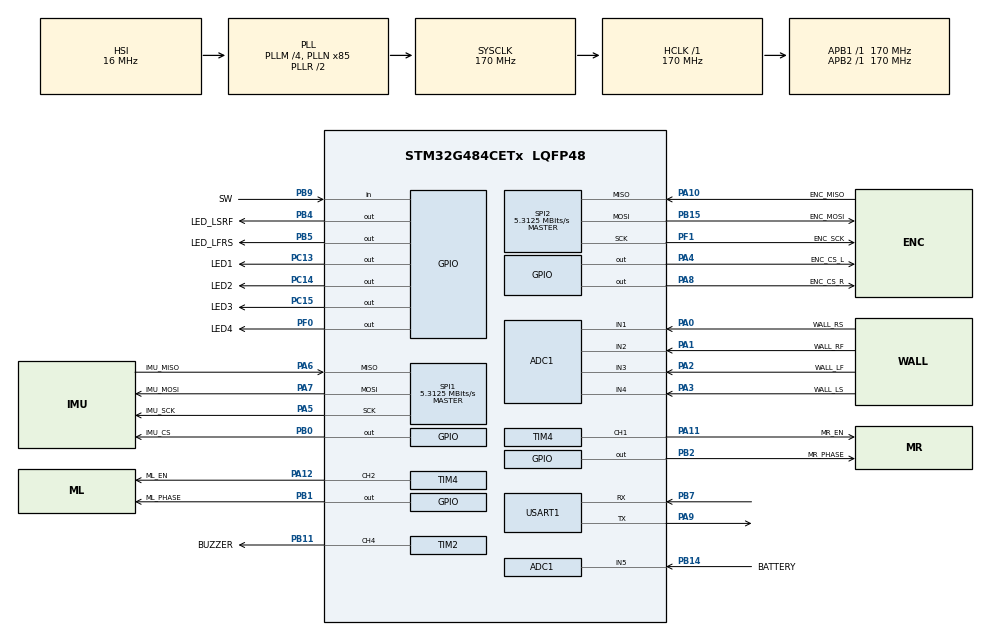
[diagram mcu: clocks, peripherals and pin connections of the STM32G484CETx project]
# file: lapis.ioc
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ADC1.Channel-0\#ChannelRegularConversion=ADC_CHANNEL_1
ADC1.Channel-1\#ChannelRegularConversion=ADC_CHANNEL_2
ADC1.Channel-2\#ChannelRegularConversion=ADC_CHANNEL_3
ADC1.Channel-3\#ChannelRegularConversion=ADC_CHANNEL_4
ADC1.Channel-4\#ChannelRegularConversion=ADC_CHANNEL_5
ADC1.ClockPrescaler=ADC_CLOCK_ASYNC_DIV4
ADC1.ContinuousConvMode=ENABLE
ADC1.DMAContinuousRequests=ENABLE
ADC1.NbrOfConversion=5
ADC1.NbrOfConversionFlag=1
ADC1.OffsetNumber-0\#ChannelRegularConversion=ADC_OFFSET_NONE
ADC1.OffsetNumber-1\#ChannelRegularConversion=ADC_OFFSET_NONE
ADC1.OffsetNumber-2\#ChannelRegularConversion=ADC_OFFSET_NONE
ADC1.OffsetNumber-3\#ChannelRegularConversion=ADC_OFFSET_NONE
ADC1.OffsetNumber-4\#ChannelRegularConversion=ADC_OFFSET_NONE
ADC1.Rank-0\#ChannelRegularConversion=1
ADC1.Rank-1\#ChannelRegularConversion=2
ADC1.Rank-2\#ChannelRegularConversion=3
ADC1.Rank-3\#ChannelRegularConversion=4
ADC1.Rank-4\#ChannelRegularConversion=5
ADC1.SamplingTime-0\#ChannelRegularConversion=ADC_SAMPLETIME_47CYCLES_5
ADC1.SamplingTime-1\#ChannelRegularConversion=ADC_SAMPLETIME_47CYCLES_5
ADC1.SamplingTime-2\#ChannelRegularConversion=ADC_SAMPLETIME_47CYCLES_5
ADC1.SamplingTime-3\#ChannelRegularConversion=ADC_SAMPLETIME_47CYCLES_5
ADC1.SamplingTime-4\#ChannelRegularConversion=ADC_SAMPLETIME_47CYCLES_5
ADC1.master=1
Dma.ADC1.0.Direction=DMA_PERIPH_TO_MEMORY
Dma.ADC1.0.EventEnable=DISABLE
Dma.ADC1.0.Instance=DMA1_Channel1
Dma.ADC1.0.MemDataAlignment=DMA_MDATAALIGN_HALFWORD
Dma.ADC1.0.MemInc=DMA_MINC_ENABLE
Dma.ADC1.0.Mode=DMA_CIRCULAR
Dma.ADC1.0.PeriphDataAlignment=DMA_PDATAALIGN_HALFWORD
Dma.ADC1.0.PeriphInc=DMA_PINC_DISABLE
Dma.ADC1.0.Polarity=HAL_DMAMUX_REQ_GEN_RISING
Dma.ADC1.0.Priority=DMA_PRIORITY_LOW
Dma.ADC1.0.RequestNumber=1
Dma.ADC1.0.SignalID=NONE
Dma.ADC1.0.SyncEnable=DISABLE
Dma.ADC1.0.SyncPolarity=HAL_DMAMUX_SYNC_NO_EVENT
Dma.ADC1.0.SyncRequestNumber=1
Dma.ADC1.0.SyncSignalID=NONE
Dma.Request0=ADC1
Dma.Request1=USART1_TX
Dma.USART1_TX.1.Direction=DMA_MEMORY_TO_PERIPH
Dma.USART1_TX.1.EventEnable=DISABLE
Dma.USART1_TX.1.Instance=DMA2_Channel1
Dma.USART1_TX.1.MemDataAlignment=DMA_MDATAALIGN_BYTE
Dma.USART1_TX.1.MemInc=DMA_MINC_ENABLE
Dma.USART1_TX.1.Mode=DMA_NORMAL
Dma.USART1_TX.1.PeriphDataAlignment=DMA_PDATAALIGN_BYTE
Dma.USART1_TX.1.PeriphInc=DMA_PINC_DISABLE
Dma.USART1_TX.1.Polarity=HAL_DMAMUX_REQ_GEN_RISING
Dma.USART1_TX.1.Priority=DMA_PRIORITY_LOW
Dma.USART1_TX.1.RequestNumber=1
Dma.USART1_TX.1.SignalID=NONE
Dma.USART1_TX.1.SyncEnable=DISABLE
Dma.USART1_TX.1.SyncPolarity=HAL_DMAMUX_SYNC_NO_EVENT
Dma.USART1_TX.1.SyncRequestNumber=1
Dma.USART1_TX.1.SyncSignalID=NONE
Mcu.Family=STM32G4
Mcu.Name=STM32G484CETx
Mcu.Package=LQFP48
NVIC.DMA1_Channel1_IRQn=true\:1\:0\:true\:false\:true\:false\:true\:true
NVIC.DMA2_Channel1_IRQn=true\:0\:0\:false\:false\:true\:false\:true\:true
NVIC.FLASH_IRQn=true\:0\:0\:false\:false\:true\:true\:true\:true
NVIC.PriorityGroup=NVIC_PRIORITYGROUP_4
NVIC.TIM1_BRK_TIM15_IRQn=true\:0\:0\:true\:false\:true\:true\:true\:true
NVIC.TIM1_CC_IRQn=true\:0\:0\:false\:false\:true\:true\:true\:true
NVIC.TIM1_TRG_COM_TIM17_IRQn=true\:0\:0\:false\:false\:true\:true\:true\:true
NVIC.TIM1_UP_TIM16_IRQn=true\:0\:0\:true\:false\:true\:true\:true\:true
NVIC.TIM3_IRQn=true\:0\:0\:true\:false\:true\:true\:true\:true
NVIC.TIM5_IRQn=true\:0\:0\:true\:false\:true\:true\:true\:true
PA0.GPIO_Label=WALL_RS
PA0.Mode=IN1-Single-Ended
PA0.Signal=ADC1_IN1
PA1.GPIO_Label=WALL_RF
PA1.Mode=IN2-Single-Ended
PA1.Signal=ADC1_IN2
PA10.GPIO_Label=ENC_MISO
PA10.Mode=Full_Duplex_Master
PA10.Signal=SPI2_MISO
PA11.GPIO_Label=MR_EN
PA11.Signal=S_TIM4_CH1
PA12.GPIO_Label=ML_EN
PA12.Signal=S_TIM4_CH2
PA13.Mode=Serial_Wire
PA13.Signal=SYS_JTMS-SWDIO
PA14.Mode=Serial_Wire
PA14.Signal=SYS_JTCK-SWCLK
PA2.GPIO_Label=WALL_LF
PA2.Mode=IN3-Single-Ended
PA2.Signal=ADC1_IN3
PA3.GPIO_Label=WALL_LS
PA3.Mode=IN4-Single-Ended
PA3.Signal=ADC1_IN4
PA4.GPIO_Label=ENC_CS_L
PA4.Signal=GPIO_Output
PA5.GPIO_Label=IMU_SCK
PA5.Mode=Full_Duplex_Master
PA5.Signal=SPI1_SCK
PA6.GPIO_Label=IMU_MISO
PA6.Mode=Full_Duplex_Master
PA6.Signal=SPI1_MISO
PA7.GPIO_Label=IMU_MOSI
PA7.Mode=Full_Duplex_Master
PA7.Signal=SPI1_MOSI
PA8.GPIO_Label=ENC_CS_R
PA8.Signal=GPIO_Output
PA9.Mode=Asynchronous
PA9.Signal=USART1_TX
PB0.GPIO_Label=IMU_CS
PB0.Signal=GPIO_Output
PB1.GPIO_Label=ML_PHASE
PB1.Signal=GPIO_Output
PB11.GPIO_Label=BUZZER
PB11.Signal=S_TIM2_CH4
PB14.GPIO_Label=BATTERY
PB14.Mode=IN5-Single-Ended
PB14.Signal=ADC1_IN5
PB15.GPIO_Label=ENC_MOSI
PB15.Mode=Full_Duplex_Master
PB15.Signal=SPI2_MOSI
PB2.GPIO_Label=MR_PHASE
PB2.Signal=GPIO_Output
PB4.GPIO_Label=LED_LSRF
PB4.Signal=GPIO_Output
PB5.GPIO_Label=LED_LFRS
PB5.Signal=GPIO_Output
PB7.Mode=Asynchronous
PB7.Signal=USART1_RX
PB9.GPIO_Label=SW
PB9.Signal=GPIO_Input
PC13.GPIO_Label=LED1
PC13.Signal=GPIO_Output
PC14-OSC32_IN.GPIO_Label=LED2
PC14-OSC32_IN.Signal=GPIO_Output
PC15-OSC32_OUT.GPIO_Label=LED3
PC15-OSC32_OUT.Signal=GPIO_Output
PF0-OSC_IN.GPIO_Label=LED4
PF0-OSC_IN.Signal=GPIO_Output
PF1-OSC_OUT.GPIO_Label=ENC_SCK
PF1-OSC_OUT.Mode=Full_Duplex_Master
PF1-OSC_OUT.Signal=SPI2_SCK
ProjectManager.HeapSize=0x200
ProjectManager.StackSize=0x400
ProjectManager.TargetToolchain=STM32CubeIDE
RCC.ADC12Freq_Value=170000000
RCC.ADC345Freq_Value=170000000
RCC.AHBFreq_Value=170000000
RCC.APB1Freq_Value=170000000
RCC.APB1TimFreq_Value=170000000
RCC.APB2Freq_Value=170000000
RCC.APB2TimFreq_Value=170000000
RCC.CortexFreq_Value=170000000
RCC.EXTERNAL_CLOCK_VALUE=12288000
RCC.HCLKFreq_Value=170000000
RCC.HSE_VALUE=8000000
RCC.HSI48_VALUE=48000000
RCC.HSI_VALUE=16000000
RCC.LSE_VALUE=32768
RCC.PLLM=RCC_PLLM_DIV4
RCC.PLLN=85
RCC.SYSCLKFreq_VALUE=170000000
RCC.SYSCLKSource=RCC_SYSCLKSOURCE_PLLCLK
RCC.USBFreq_Value=170000000
RCC.VCOOutputFreq_Value=340000000
SH.S_TIM2_CH4.0=TIM2_CH4,PWM Generation4 CH4
SH.S_TIM4_CH1.0=TIM4_CH1,PWM Generation1 CH1
SH.S_TIM4_CH2.0=TIM4_CH2,PWM Generation2 CH2
SPI1.BaudRatePrescaler=SPI_BAUDRATEPRESCALER_32
SPI1.CalculateBaudRate=5.3125 MBits/s
SPI1.DataSize=SPI_DATASIZE_8BIT
SPI1.Direction=SPI_DIRECTION_2LINES
SPI1.Mode=SPI_MODE_MASTER
SPI1.VirtualType=VM_MASTER
SPI2.BaudRatePrescaler=SPI_BAUDRATEPRESCALER_32
SPI2.CLKPhase=SPI_PHASE_2EDGE
SPI2.CalculateBaudRate=5.3125 MBits/s
SPI2.DataSize=SPI_DATASIZE_16BIT
SPI2.Direction=SPI_DIRECTION_2LINES
SPI2.Mode=SPI_MODE_MASTER
SPI2.VirtualType=VM_MASTER
TIM1.PeriodNoDither=169
TIM1.Prescaler=999
TIM2.Channel-PWM\ Generation4\ CH4=TIM_CHANNEL_4
TIM2.PeriodNoDither=0
TIM2.Prescaler=0
TIM3.PeriodNoDither=424
TIM3.Prescaler=99
TIM4.Channel-PWM\ Generation1\ CH1=TIM_CHANNEL_1
TIM4.Channel-PWM\ Generation2\ CH2=TIM_CHANNEL_2
TIM4.PeriodNoDither=999
TIM5.PeriodNoDither=169
TIM5.Prescaler=999
USART1.VirtualMode-Asynchronous=VM_ASYNC
VP_SYS_VS_DBSignals.Mode=DisableDeadBatterySignals
VP_TIM1_VS_ClockSourceINT.Mode=Internal
VP_TIM3_VS_ClockSourceINT.Mode=Internal
VP_TIM5_VS_ClockSourceINT.Mode=Internal
board=custom

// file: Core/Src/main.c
/* USER CODE BEGIN Header */
/**
 ******************************************************************************
 * @file           : main.c
 * @brief          : Main program body
 ******************************************************************************
 * @attention
 *
 * <h2><center>&copy; Copyright (c) 2021 STMicroelectronics.
 * All rights reserved.</center></h2>
 *
 * This software component is licensed by ST under BSD 3-Clause license,
 * the "License"; You may not use this file except in compliance with the
 * License. You may obtain a copy of the License at:
 *                        opensource.org/licenses/BSD-3-Clause
 *
 ******************************************************************************
 */
/* USER CODE END Header */
#include "main.h"

/* USER CODE BEGIN Includes */
#include"ICM20602.h"
#include "AS5047P.h"
#include"timer.h"
#include"lapis.h"
#include"motor.h"
#include "wallsensor.h"
#include"adc.h"
#include"UI.h"
/* USER CODE END Includes */

 ADC_HandleTypeDef hadc1;
DMA_HandleTypeDef hdma_adc1;

SPI_HandleTypeDef hspi1;
SPI_HandleTypeDef hspi2;

TIM_HandleTypeDef htim1;
TIM_HandleTypeDef htim2;
TIM_HandleTypeDef htim3;
TIM_HandleTypeDef htim4;
TIM_HandleTypeDef htim5;

UART_HandleTypeDef huart1;
DMA_HandleTypeDef hdma_usart1_tx;

void SystemClock_Config(void);
static void MX_GPIO_Init(void);
static void MX_DMA_Init(void);
static void MX_ADC1_Init(void);
static void MX_SPI1_Init(void);
static void MX_SPI2_Init(void);
static void MX_TIM1_Init(void);
static void MX_TIM2_Init(void);
static void MX_TIM4_Init(void);
static void MX_USART1_UART_Init(void);
static void MX_TIM3_Init(void);
static void MX_TIM5_Init(void);

int main(void)
{

  /* MCU Configuration--------------------------------------------------------*/

  /* Reset of all peripherals, Initializes the Flash interface and the Systick. */
  HAL_Init();

  /* Configure the system clock */
  SystemClock_Config();

  /* Initialize all configured peripherals */
  MX_GPIO_Init();
  MX_DMA_Init();
  MX_ADC1_Init();
  MX_SPI1_Init();
  MX_SPI2_Init();
  MX_TIM1_Init();
  MX_TIM2_Init();
  MX_TIM4_Init();
  MX_USART1_UART_Init();
  MX_TIM3_Init();
  MX_TIM5_Init();

  /* Infinite loop */
	while (1) {

    /* USER CODE BEGIN 3 */

		lapis();
	}
  /* USER CODE END 3 */
}

void SystemClock_Config(void)
{
  RCC_OscInitTypeDef RCC_OscInitStruct = {0};
  RCC_ClkInitTypeDef RCC_ClkInitStruct = {0};

  /** Configure the main internal regulator output voltage
  */
  HAL_PWREx_ControlVoltageScaling(PWR_REGULATOR_VOLTAGE_SCALE1_BOOST);

  /** Initializes the RCC Oscillators according to the specified parameters
  * in the RCC_OscInitTypeDef structure.
  */
  RCC_OscInitStruct.OscillatorType = RCC_OSCILLATORTYPE_HSI;
  RCC_OscInitStruct.HSIState = RCC_HSI_ON;
  RCC_OscInitStruct.HSICalibrationValue = RCC_HSICALIBRATION_DEFAULT;
  RCC_OscInitStruct.PLL.PLLState = RCC_PLL_ON;
  RCC_OscInitStruct.PLL.PLLSource = RCC_PLLSOURCE_HSI;
  RCC_OscInitStruct.PLL.PLLM = RCC_PLLM_DIV4;
  RCC_OscInitStruct.PLL.PLLN = 85;
  RCC_OscInitStruct.PLL.PLLP = RCC_PLLP_DIV2;
  RCC_OscInitStruct.PLL.PLLQ = RCC_PLLQ_DIV2;
  RCC_OscInitStruct.PLL.PLLR = RCC_PLLR_DIV2;
  if (HAL_RCC_OscConfig(&RCC_OscInitStruct) != HAL_OK)
  {
    Error_Handler();
  }

  /** Initializes the CPU, AHB and APB buses clocks
  */
  RCC_ClkInitStruct.ClockType = RCC_CLOCKTYPE_HCLK|RCC_CLOCKTYPE_SYSCLK
                              |RCC_CLOCKTYPE_PCLK1|RCC_CLOCKTYPE_PCLK2;
  RCC_ClkInitStruct.SYSCLKSource = RCC_SYSCLKSOURCE_PLLCLK;
  RCC_ClkInitStruct.AHBCLKDivider = RCC_SYSCLK_DIV1;
  RCC_ClkInitStruct.APB1CLKDivider = RCC_HCLK_DIV1;
  RCC_ClkInitStruct.APB2CLKDivider = RCC_HCLK_DIV1;

  if (HAL_RCC_ClockConfig(&RCC_ClkInitStruct, FLASH_LATENCY_4) != HAL_OK)
  {
    Error_Handler();
  }
}

static void MX_ADC1_Init(void)
{

  ADC_MultiModeTypeDef multimode = {0};
  ADC_ChannelConfTypeDef sConfig = {0};

  /** Common config
  */
  hadc1.Instance = ADC1;
  hadc1.Init.ClockPrescaler = ADC_CLOCK_ASYNC_DIV4;
  hadc1.Init.Resolution = ADC_RESOLUTION_12B;
  hadc1.Init.DataAlign = ADC_DATAALIGN_RIGHT;
  hadc1.Init.GainCompensation = 0;
  hadc1.Init.ScanConvMode = ADC_SCAN_ENABLE;
  hadc1.Init.EOCSelection = ADC_EOC_SINGLE_CONV;
  hadc1.Init.LowPowerAutoWait = DISABLE;
  hadc1.Init.ContinuousConvMode = ENABLE;
  hadc1.Init.NbrOfConversion = 5;
  hadc1.Init.DiscontinuousConvMode = DISABLE;
  hadc1.Init.ExternalTrigConv = ADC_SOFTWARE_START;
  hadc1.Init.ExternalTrigConvEdge = ADC_EXTERNALTRIGCONVEDGE_NONE;
  hadc1.Init.DMAContinuousRequests = ENABLE;
  hadc1.Init.Overrun = ADC_OVR_DATA_PRESERVED;
  hadc1.Init.OversamplingMode = DISABLE;
  if (HAL_ADC_Init(&hadc1) != HAL_OK)
  {
    Error_Handler();
  }

  /** Configure the ADC multi-mode
  */
  multimode.Mode = ADC_MODE_INDEPENDENT;
  if (HAL_ADCEx_MultiModeConfigChannel(&hadc1, &multimode) != HAL_OK)
  {
    Error_Handler();
  }

  /** Configure Regular Channel
  */
  sConfig.Channel = ADC_CHANNEL_1;
  sConfig.Rank = ADC_REGULAR_RANK_1;
  sConfig.SamplingTime = ADC_SAMPLETIME_47CYCLES_5;
  sConfig.SingleDiff = ADC_SINGLE_ENDED;
  sConfig.OffsetNumber = ADC_OFFSET_NONE;
  sConfig.Offset = 0;
  if (HAL_ADC_ConfigChannel(&hadc1, &sConfig) != HAL_OK)
  {
    Error_Handler();
  }

  /** Configure Regular Channel
  */
  sConfig.Channel = ADC_CHANNEL_2;
  sConfig.Rank = ADC_REGULAR_RANK_2;
  if (HAL_ADC_ConfigChannel(&hadc1, &sConfig) != HAL_OK)
  {
    Error_Handler();
  }

  /** Configure Regular Channel
  */
  sConfig.Channel = ADC_CHANNEL_3;
  sConfig.Rank = ADC_REGULAR_RANK_3;
  if (HAL_ADC_ConfigChannel(&hadc1, &sConfig) != HAL_OK)
  {
    Error_Handler();
  }

  /** Configure Regular Channel
  */
  sConfig.Channel = ADC_CHANNEL_4;
  sConfig.Rank = ADC_REGULAR_RANK_4;
  if (HAL_ADC_ConfigChannel(&hadc1, &sConfig) != HAL_OK)
  {
    Error_Handler();
  }

  /** Configure Regular Channel
  */
  sConfig.Channel = ADC_CHANNEL_5;
  sConfig.Rank = ADC_REGULAR_RANK_5;
  if (HAL_ADC_ConfigChannel(&hadc1, &sConfig) != HAL_OK)
  {
    Error_Handler();
  }

}

static void MX_SPI1_Init(void)
{

  /* SPI1 parameter configuration*/
  hspi1.Instance = SPI1;
  hspi1.Init.Mode = SPI_MODE_MASTER;
  hspi1.Init.Direction = SPI_DIRECTION_2LINES;
  hspi1.Init.DataSize = SPI_DATASIZE_8BIT;
  hspi1.Init.CLKPolarity = SPI_POLARITY_LOW;
  hspi1.Init.CLKPhase = SPI_PHASE_1EDGE;
  hspi1.Init.NSS = SPI_NSS_SOFT;
  hspi1.Init.BaudRatePrescaler = SPI_BAUDRATEPRESCALER_32;
  hspi1.Init.FirstBit = SPI_FIRSTBIT_MSB;
  hspi1.Init.TIMode = SPI_TIMODE_DISABLE;
  hspi1.Init.CRCCalculation = SPI_CRCCALCULATION_DISABLE;
  hspi1.Init.CRCPolynomial = 7;
  hspi1.Init.CRCLength = SPI_CRC_LENGTH_DATASIZE;
  hspi1.Init.NSSPMode = SPI_NSS_PULSE_ENABLE;
  if (HAL_SPI_Init(&hspi1) != HAL_OK)
  {
    Error_Handler();
  }

}

static void MX_SPI2_Init(void)
{

  /* SPI2 parameter configuration*/
  hspi2.Instance = SPI2;
  hspi2.Init.Mode = SPI_MODE_MASTER;
  hspi2.Init.Direction = SPI_DIRECTION_2LINES;
  hspi2.Init.DataSize = SPI_DATASIZE_16BIT;
  hspi2.Init.CLKPolarity = SPI_POLARITY_LOW;
  hspi2.Init.CLKPhase = SPI_PHASE_2EDGE;
  hspi2.Init.NSS = SPI_NSS_SOFT;
  hspi2.Init.BaudRatePrescaler = SPI_BAUDRATEPRESCALER_32;
  hspi2.Init.FirstBit = SPI_FIRSTBIT_MSB;
  hspi2.Init.TIMode = SPI_TIMODE_DISABLE;
  hspi2.Init.CRCCalculation = SPI_CRCCALCULATION_DISABLE;
  hspi2.Init.CRCPolynomial = 7;
  hspi2.Init.CRCLength = SPI_CRC_LENGTH_DATASIZE;
  hspi2.Init.NSSPMode = SPI_NSS_PULSE_DISABLE;
  if (HAL_SPI_Init(&hspi2) != HAL_OK)
  {
    Error_Handler();
  }

}

static void MX_TIM1_Init(void)
{

  TIM_ClockConfigTypeDef sClockSourceConfig = {0};
  TIM_MasterConfigTypeDef sMasterConfig = {0};

  htim1.Instance = TIM1;
  htim1.Init.Prescaler = 999;
  htim1.Init.CounterMode = TIM_COUNTERMODE_UP;
  htim1.Init.Period = 169;
  htim1.Init.ClockDivision = TIM_CLOCKDIVISION_DIV1;
  htim1.Init.RepetitionCounter = 0;
  htim1.Init.AutoReloadPreload = TIM_AUTORELOAD_PRELOAD_DISABLE;
  if (HAL_TIM_Base_Init(&htim1) != HAL_OK)
  {
    Error_Handler();
  }
  sClockSourceConfig.ClockSource = TIM_CLOCKSOURCE_INTERNAL;
  if (HAL_TIM_ConfigClockSource(&htim1, &sClockSourceConfig) != HAL_OK)
  {
    Error_Handler();
  }
  sMasterConfig.MasterOutputTrigger = TIM_TRGO_RESET;
  sMasterConfig.MasterOutputTrigger2 = TIM_TRGO2_RESET;
  sMasterConfig.MasterSlaveMode = TIM_MASTERSLAVEMODE_DISABLE;
  if (HAL_TIMEx_MasterConfigSynchronization(&htim1, &sMasterConfig) != HAL_OK)
  {
    Error_Handler();
  }

}

static void MX_TIM2_Init(void)
{

  TIM_MasterConfigTypeDef sMasterConfig = {0};
  TIM_OC_InitTypeDef sConfigOC = {0};

  htim2.Instance = TIM2;
  htim2.Init.Prescaler = 0;
  htim2.Init.CounterMode = TIM_COUNTERMODE_UP;
  htim2.Init.Period = 0;
  htim2.Init.ClockDivision = TIM_CLOCKDIVISION_DIV1;
  htim2.Init.AutoReloadPreload = TIM_AUTORELOAD_PRELOAD_DISABLE;
  if (HAL_TIM_PWM_Init(&htim2) != HAL_OK)
  {
    Error_Handler();
  }
  sMasterConfig.MasterOutputTrigger = TIM_TRGO_RESET;
  sMasterConfig.MasterSlaveMode = TIM_MASTERSLAVEMODE_DISABLE;
  if (HAL_TIMEx_MasterConfigSynchronization(&htim2, &sMasterConfig) != HAL_OK)
  {
    Error_Handler();
  }
  sConfigOC.OCMode = TIM_OCMODE_PWM1;
  sConfigOC.Pulse = 0;
  sConfigOC.OCPolarity = TIM_OCPOLARITY_HIGH;
  sConfigOC.OCFastMode = TIM_OCFAST_DISABLE;
  if (HAL_TIM_PWM_ConfigChannel(&htim2, &sConfigOC, TIM_CHANNEL_4) != HAL_OK)
  {
    Error_Handler();
  }
  HAL_TIM_MspPostInit(&htim2);

}

static void MX_TIM3_Init(void)
{

  TIM_ClockConfigTypeDef sClockSourceConfig = {0};
  TIM_MasterConfigTypeDef sMasterConfig = {0};

  htim3.Instance = TIM3;
  htim3.Init.Prescaler = 99;
  htim3.Init.CounterMode = TIM_COUNTERMODE_UP;
  htim3.Init.Period = 424;
  htim3.Init.ClockDivision = TIM_CLOCKDIVISION_DIV1;
  htim3.Init.AutoReloadPreload = TIM_AUTORELOAD_PRELOAD_DISABLE;
  if (HAL_TIM_Base_Init(&htim3) != HAL_OK)
  {
    Error_Handler();
  }
  sClockSourceConfig.ClockSource = TIM_CLOCKSOURCE_INTERNAL;
  if (HAL_TIM_ConfigClockSource(&htim3, &sClockSourceConfig) != HAL_OK)
  {
    Error_Handler();
  }
  sMasterConfig.MasterOutputTrigger = TIM_TRGO_RESET;
  sMasterConfig.MasterSlaveMode = TIM_MASTERSLAVEMODE_DISABLE;
  if (HAL_TIMEx_MasterConfigSynchronization(&htim3, &sMasterConfig) != HAL_OK)
  {
    Error_Handler();
  }

}

static void MX_TIM4_Init(void)
{

  TIM_MasterConfigTypeDef sMasterConfig = {0};
  TIM_OC_InitTypeDef sConfigOC = {0};

  htim4.Instance = TIM4;
  htim4.Init.Prescaler = 0;
  htim4.Init.CounterMode = TIM_COUNTERMODE_UP;
  htim4.Init.Period = 999;
  htim4.Init.ClockDivision = TIM_CLOCKDIVISION_DIV1;
  htim4.Init.AutoReloadPreload = TIM_AUTORELOAD_PRELOAD_DISABLE;
  if (HAL_TIM_PWM_Init(&htim4) != HAL_OK)
  {
    Error_Handler();
  }
  sMasterConfig.MasterOutputTrigger = TIM_TRGO_RESET;
  sMasterConfig.MasterSlaveMode = TIM_MASTERSLAVEMODE_DISABLE;
  if (HAL_TIMEx_MasterConfigSynchronization(&htim4, &sMasterConfig) != HAL_OK)
  {
    Error_Handler();
  }
  sConfigOC.OCMode = TIM_OCMODE_PWM1;
  sConfigOC.Pulse = 0;
  sConfigOC.OCPolarity = TIM_OCPOLARITY_HIGH;
  sConfigOC.OCFastMode = TIM_OCFAST_DISABLE;
  if (HAL_TIM_PWM_ConfigChannel(&htim4, &sConfigOC, TIM_CHANNEL_1) != HAL_OK)
  {
    Error_Handler();
  }
  if (HAL_TIM_PWM_ConfigChannel(&htim4, &sConfigOC, TIM_CHANNEL_2) != HAL_OK)
  {
    Error_Handler();
  }
  HAL_TIM_MspPostInit(&htim4);

}

static void MX_TIM5_Init(void)
{

  TIM_ClockConfigTypeDef sClockSourceConfig = {0};
  TIM_MasterConfigTypeDef sMasterConfig = {0};

  htim5.Instance = TIM5;
  htim5.Init.Prescaler = 999;
  htim5.Init.CounterMode = TIM_COUNTERMODE_UP;
  htim5.Init.Period = 169;
  htim5.Init.ClockDivision = TIM_CLOCKDIVISION_DIV1;
  htim5.Init.AutoReloadPreload = TIM_AUTORELOAD_PRELOAD_DISABLE;
  if (HAL_TIM_Base_Init(&htim5) != HAL_OK)
  {
    Error_Handler();
  }
  sClockSourceConfig.ClockSource = TIM_CLOCKSOURCE_INTERNAL;
  if (HAL_TIM_ConfigClockSource(&htim5, &sClockSourceConfig) != HAL_OK)
  {
    Error_Handler();
  }
  sMasterConfig.MasterOutputTrigger = TIM_TRGO_RESET;
  sMasterConfig.MasterSlaveMode = TIM_MASTERSLAVEMODE_DISABLE;
  if (HAL_TIMEx_MasterConfigSynchronization(&htim5, &sMasterConfig) != HAL_OK)
  {
    Error_Handler();
  }

}

static void MX_USART1_UART_Init(void)
{

  huart1.Instance = USART1;
  huart1.Init.BaudRate = 115200;
  huart1.Init.WordLength = UART_WORDLENGTH_8B;
  huart1.Init.StopBits = UART_STOPBITS_1;
  huart1.Init.Parity = UART_PARITY_NONE;
  huart1.Init.Mode = UART_MODE_TX_RX;
  huart1.Init.HwFlowCtl = UART_HWCONTROL_NONE;
  huart1.Init.OverSampling = UART_OVERSAMPLING_16;
  huart1.Init.OneBitSampling = UART_ONE_BIT_SAMPLE_DISABLE;
  huart1.Init.ClockPrescaler = UART_PRESCALER_DIV1;
  huart1.AdvancedInit.AdvFeatureInit = UART_ADVFEATURE_NO_INIT;
  if (HAL_UART_Init(&huart1) != HAL_OK)
  {
    Error_Handler();
  }
  if (HAL_UARTEx_SetTxFifoThreshold(&huart1, UART_TXFIFO_THRESHOLD_1_8) != HAL_OK)
  {
    Error_Handler();
  }
  if (HAL_UARTEx_SetRxFifoThreshold(&huart1, UART_RXFIFO_THRESHOLD_1_8) != HAL_OK)
  {
    Error_Handler();
  }
  if (HAL_UARTEx_DisableFifoMode(&huart1) != HAL_OK)
  {
    Error_Handler();
  }

}

static void MX_DMA_Init(void)
{

  /* DMA controller clock enable */
  __HAL_RCC_DMAMUX1_CLK_ENABLE();
  __HAL_RCC_DMA1_CLK_ENABLE();
  __HAL_RCC_DMA2_CLK_ENABLE();

  /* DMA interrupt init */
  /* DMA1_Channel1_IRQn interrupt configuration */
  HAL_NVIC_SetPriority(DMA1_Channel1_IRQn, 1, 0);
  HAL_NVIC_EnableIRQ(DMA1_Channel1_IRQn);
  /* DMA2_Channel1_IRQn interrupt configuration */
  HAL_NVIC_SetPriority(DMA2_Channel1_IRQn, 0, 0);
  HAL_NVIC_EnableIRQ(DMA2_Channel1_IRQn);

}

static void MX_GPIO_Init(void)
{
  GPIO_InitTypeDef GPIO_InitStruct = {0};

  /* GPIO Ports Clock Enable */
  __HAL_RCC_GPIOC_CLK_ENABLE();
  __HAL_RCC_GPIOF_CLK_ENABLE();
  __HAL_RCC_GPIOA_CLK_ENABLE();
  __HAL_RCC_GPIOB_CLK_ENABLE();

  /*Configure GPIO pin Output Level */
  HAL_GPIO_WritePin(GPIOC, LED1_Pin|LED2_Pin|LED3_Pin, GPIO_PIN_RESET);

  /*Configure GPIO pin Output Level */
  HAL_GPIO_WritePin(LED4_GPIO_Port, LED4_Pin, GPIO_PIN_RESET);

  /*Configure GPIO pin Output Level */
  HAL_GPIO_WritePin(GPIOA, ENC_CS_L_Pin|ENC_CS_R_Pin, GPIO_PIN_RESET);

  /*Configure GPIO pin Output Level */
  HAL_GPIO_WritePin(GPIOB, IMU_CS_Pin|ML_PHASE_Pin|MR_PHASE_Pin|LED_LSRF_Pin
                          |LED_LFRS_Pin, GPIO_PIN_RESET);

  /*Configure GPIO pins : LED1_Pin LED2_Pin LED3_Pin */
  GPIO_InitStruct.Pin = LED1_Pin|LED2_Pin|LED3_Pin;
  GPIO_InitStruct.Mode = GPIO_MODE_OUTPUT_PP;
  GPIO_InitStruct.Pull = GPIO_NOPULL;
  GPIO_InitStruct.Speed = GPIO_SPEED_FREQ_LOW;
  HAL_GPIO_Init(GPIOC, &GPIO_InitStruct);

  /*Configure GPIO pin : LED4_Pin */
  GPIO_InitStruct.Pin = LED4_Pin;
  GPIO_InitStruct.Mode = GPIO_MODE_OUTPUT_PP;
  GPIO_InitStruct.Pull = GPIO_NOPULL;
  GPIO_InitStruct.Speed = GPIO_SPEED_FREQ_LOW;
  HAL_GPIO_Init(LED4_GPIO_Port, &GPIO_InitStruct);

  /*Configure GPIO pins : ENC_CS_L_Pin ENC_CS_R_Pin */
  GPIO_InitStruct.Pin = ENC_CS_L_Pin|ENC_CS_R_Pin;
  GPIO_InitStruct.Mode = GPIO_MODE_OUTPUT_PP;
  GPIO_InitStruct.Pull = GPIO_NOPULL;
  GPIO_InitStruct.Speed = GPIO_SPEED_FREQ_LOW;
  HAL_GPIO_Init(GPIOA, &GPIO_InitStruct);

  /*Configure GPIO pins : IMU_CS_Pin ML_PHASE_Pin MR_PHASE_Pin LED_LSRF_Pin
                           LED_LFRS_Pin */
  GPIO_InitStruct.Pin = IMU_CS_Pin|ML_PHASE_Pin|MR_PHASE_Pin|LED_LSRF_Pin
                          |LED_LFRS_Pin;
  GPIO_InitStruct.Mode = GPIO_MODE_OUTPUT_PP;
  GPIO_InitStruct.Pull = GPIO_NOPULL;
  GPIO_InitStruct.Speed = GPIO_SPEED_FREQ_LOW;
  HAL_GPIO_Init(GPIOB, &GPIO_InitStruct);

  /*Configure GPIO pin : SW_Pin */
  GPIO_InitStruct.Pin = SW_Pin;
  GPIO_InitStruct.Mode = GPIO_MODE_INPUT;
  GPIO_InitStruct.Pull = GPIO_NOPULL;
  HAL_GPIO_Init(SW_GPIO_Port, &GPIO_InitStruct);

}

void Error_Handler(void)
{
}
